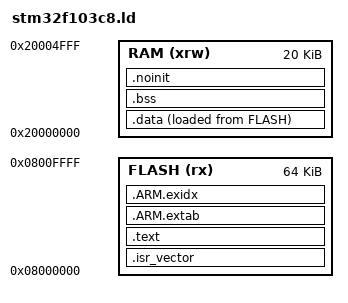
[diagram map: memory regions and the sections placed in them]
ENTRY(Reset_Handler)

_Min_Stack_Size = 0x400; /* Dự trù ban đầu 1 KiB cho MSP */
_estack = ORIGIN(RAM) + LENGTH(RAM);
__StackLimit = _estack - _Min_Stack_Size;

MEMORY
{
    FLASH (rx)  : ORIGIN = 0x08000000, LENGTH = 64K
    RAM   (xrw) : ORIGIN = 0x20000000, LENGTH = 20K
}

SECTIONS
{
    .isr_vector :
    {
        . = ALIGN(4);
        KEEP(*(.isr_vector))
        . = ALIGN(4);
    } > FLASH

    .text :
    {
        . = ALIGN(4);
        *(.text*)
        *(.rodata*)
        . = ALIGN(4);
    } > FLASH

    .ARM.extab :
    {
        *(.ARM.extab*)
    } > FLASH

    .ARM.exidx :
    {
        __exidx_start = .;
        *(.ARM.exidx*)
        __exidx_end = .;
    } > FLASH

    _sidata = LOADADDR(.data);
    .data :
    {
        . = ALIGN(4);
        _sdata = .;
        *(.data*)
        . = ALIGN(4);
        _edata = .;
    } > RAM AT> FLASH

    .bss (NOLOAD) : 
    {
        . = ALIGN(4);
        _sbss = .;
        *(.bss*)
        *(COMMON)
        . = ALIGN(4);
        _ebss = .;
    } > RAM

    .noinit (NOLOAD) :
    {
        . = ALIGN(4);
        _snoinit = .;
        *(.noinit*)
        . = ALIGN(4);
        _enoinit = .;
    } > RAM

    _end = .;

    ASSERT(_end <= __StackLimit, "RAM overflow: data/bss overlap MSP stack")
}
